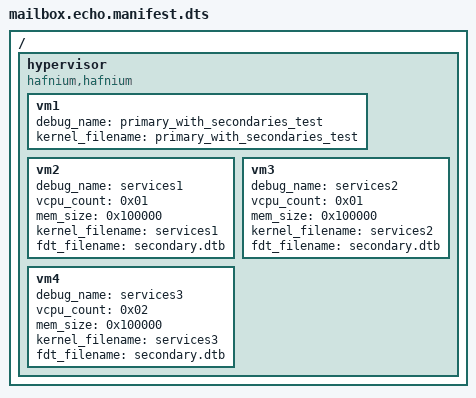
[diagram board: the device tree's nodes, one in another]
/dts-v1/;

/ {

	hypervisor {
		compatible = "hafnium,hafnium";

		vm1 {
			debug_name = "primary_with_secondaries_test";
			kernel_filename = "primary_with_secondaries_test";
		};

		vm2 {
			debug_name = "services1";
			vcpu_count = <0x01>;
			mem_size = <0x100000>;
			kernel_filename = "services1";
			fdt_filename = "secondary.dtb";
		};

		vm3 {
			debug_name = "services2";
			vcpu_count = <0x01>;
			mem_size = <0x100000>;
			kernel_filename = "services2";
			fdt_filename = "secondary.dtb";
		};

		vm4 {
			debug_name = "services3";
			vcpu_count = <0x02>;
			mem_size = <0x100000>;
			kernel_filename = "services3";
			fdt_filename = "secondary.dtb";
		};
	};
};
